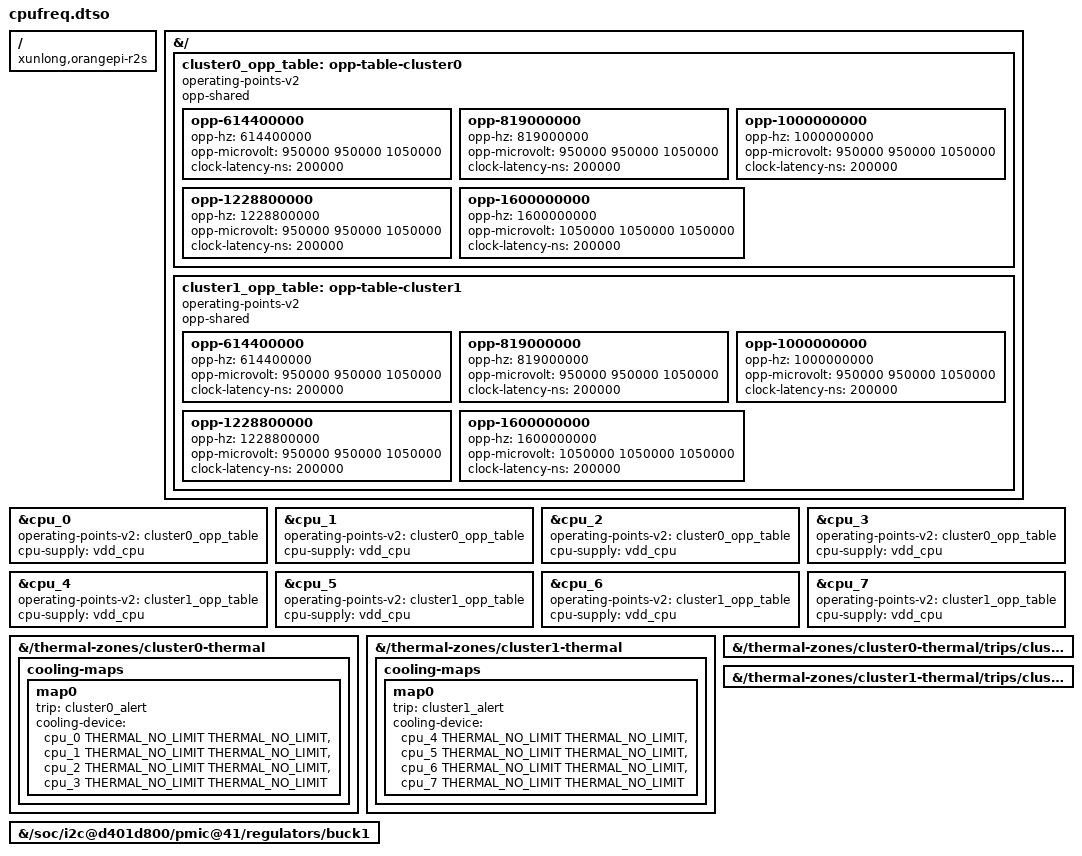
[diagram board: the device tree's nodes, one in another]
// SPDX-License-Identifier: (GPL-2.0+ OR MIT)

/dts-v1/;
/plugin/;

#include <dt-bindings/thermal/thermal.h>

/ {
	compatible = "xunlong,orangepi-r2s";

	fragment@100 {
		target-path = "/soc/i2c@d401d800/pmic@41/regulators/buck1";

		vdd_cpu: __overlay__ {
		};
	};

	fragment@101 {
		target-path = "/thermal-zones/cluster0-thermal/trips/cluster0-alert";

		cluster0_alert: __overlay__ {
		};
	};

	fragment@102 {
		target-path = "/thermal-zones/cluster1-thermal/trips/cluster1-alert";

		cluster1_alert: __overlay__ {
		};
	};
};

&{/} {
	cluster0_opp_table: opp-table-cluster0 {
		compatible = "operating-points-v2";
		opp-shared;

		opp-614400000 {
			opp-hz = /bits/ 64 <614400000>;
			opp-microvolt = <950000 950000 1050000>;
			clock-latency-ns = <200000>;
		};

		opp-819000000 {
			opp-hz = /bits/ 64 <819000000>;
			opp-microvolt = <950000 950000 1050000>;
			clock-latency-ns = <200000>;
		};

		opp-1000000000 {
			opp-hz = /bits/ 64 <1000000000>;
			opp-microvolt = <950000 950000 1050000>;
			clock-latency-ns = <200000>;
		};

		opp-1228800000 {
			opp-hz = /bits/ 64 <1228800000>;
			opp-microvolt = <950000 950000 1050000>;
			clock-latency-ns = <200000>;
		};

		opp-1600000000 {
			opp-hz = /bits/ 64 <1600000000>;
			opp-microvolt = <1050000 1050000 1050000>;
			clock-latency-ns = <200000>;
		};
	};

	cluster1_opp_table: opp-table-cluster1 {
		compatible = "operating-points-v2";
		opp-shared;

		opp-614400000 {
			opp-hz = /bits/ 64 <614400000>;
			opp-microvolt = <950000 950000 1050000>;
			clock-latency-ns = <200000>;
		};

		opp-819000000 {
			opp-hz = /bits/ 64 <819000000>;
			opp-microvolt = <950000 950000 1050000>;
			clock-latency-ns = <200000>;
		};

		opp-1000000000 {
			opp-hz = /bits/ 64 <1000000000>;
			opp-microvolt = <950000 950000 1050000>;
			clock-latency-ns = <200000>;
		};

		opp-1228800000 {
			opp-hz = /bits/ 64 <1228800000>;
			opp-microvolt = <950000 950000 1050000>;
			clock-latency-ns = <200000>;
		};

		opp-1600000000 {
			opp-hz = /bits/ 64 <1600000000>;
			opp-microvolt = <1050000 1050000 1050000>;
			clock-latency-ns = <200000>;
		};
	};
};

&cpu_0 {
	operating-points-v2 = <&cluster0_opp_table>;
	cpu-supply = <&vdd_cpu>;
	#cooling-cells = <2>;
};

&cpu_1 {
	operating-points-v2 = <&cluster0_opp_table>;
	cpu-supply = <&vdd_cpu>;
	#cooling-cells = <2>;
};

&cpu_2 {
	operating-points-v2 = <&cluster0_opp_table>;
	cpu-supply = <&vdd_cpu>;
	#cooling-cells = <2>;
};

&cpu_3 {
	operating-points-v2 = <&cluster0_opp_table>;
	cpu-supply = <&vdd_cpu>;
	#cooling-cells = <2>;
};

&cpu_4 {
	operating-points-v2 = <&cluster1_opp_table>;
	cpu-supply = <&vdd_cpu>;
	#cooling-cells = <2>;
};

&cpu_5 {
	operating-points-v2 = <&cluster1_opp_table>;
	cpu-supply = <&vdd_cpu>;
	#cooling-cells = <2>;
};

&cpu_6 {
	operating-points-v2 = <&cluster1_opp_table>;
	cpu-supply = <&vdd_cpu>;
	#cooling-cells = <2>;
};

&cpu_7 {
	operating-points-v2 = <&cluster1_opp_table>;
	cpu-supply = <&vdd_cpu>;
	#cooling-cells = <2>;
};

&{/thermal-zones/cluster0-thermal} {
	cooling-maps {
		map0 {
			trip = <&cluster0_alert>;
			cooling-device = <&cpu_0 THERMAL_NO_LIMIT THERMAL_NO_LIMIT>,
					 <&cpu_1 THERMAL_NO_LIMIT THERMAL_NO_LIMIT>,
					 <&cpu_2 THERMAL_NO_LIMIT THERMAL_NO_LIMIT>,
					 <&cpu_3 THERMAL_NO_LIMIT THERMAL_NO_LIMIT>;
		};
	};
};

&{/thermal-zones/cluster1-thermal} {
	cooling-maps {
		map0 {
			trip = <&cluster1_alert>;
			cooling-device = <&cpu_4 THERMAL_NO_LIMIT THERMAL_NO_LIMIT>,
					 <&cpu_5 THERMAL_NO_LIMIT THERMAL_NO_LIMIT>,
					 <&cpu_6 THERMAL_NO_LIMIT THERMAL_NO_LIMIT>,
					 <&cpu_7 THERMAL_NO_LIMIT THERMAL_NO_LIMIT>;
		};
	};
};
